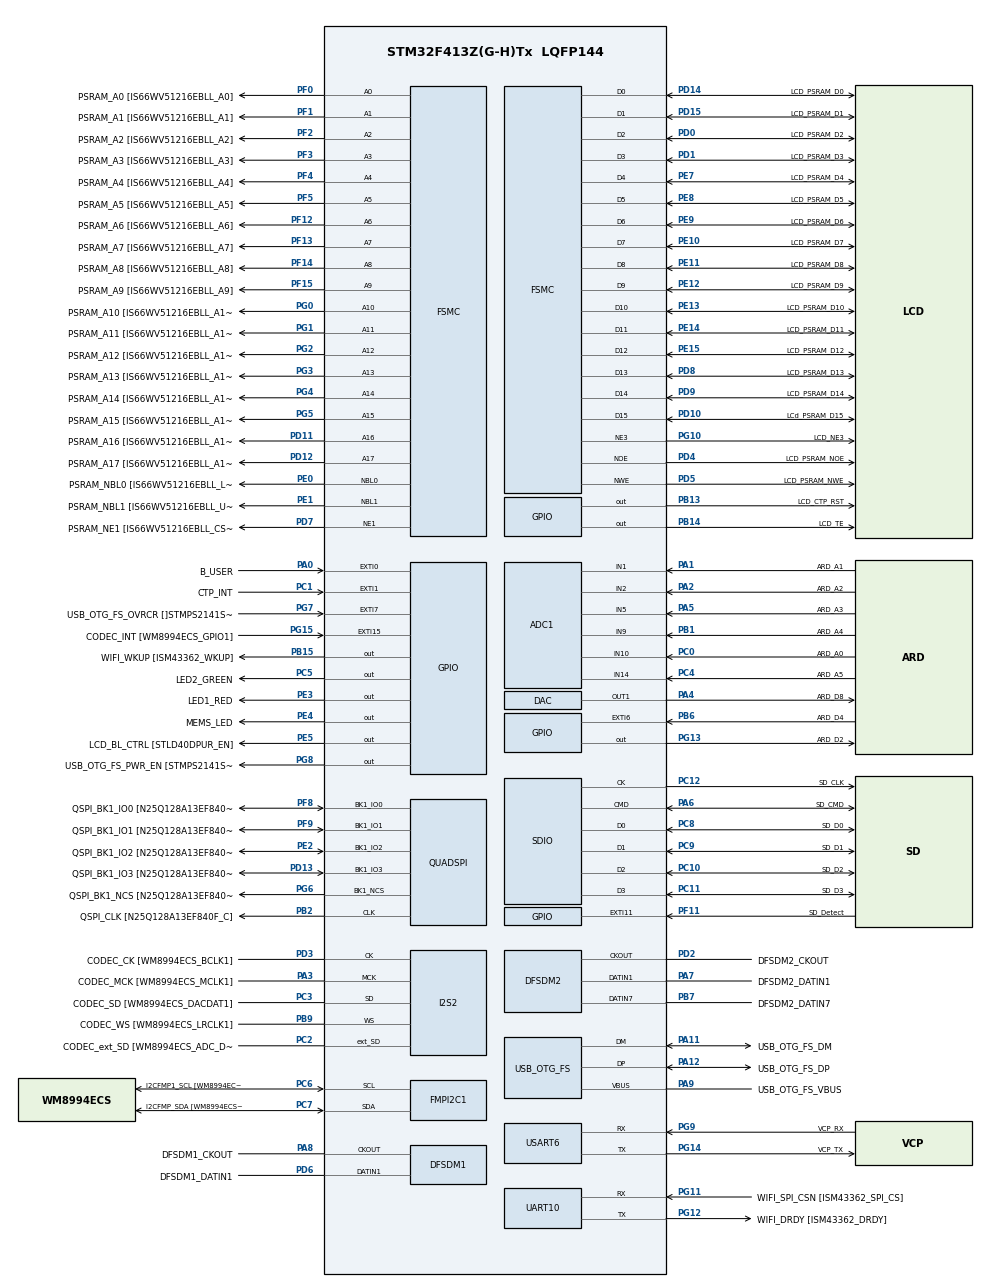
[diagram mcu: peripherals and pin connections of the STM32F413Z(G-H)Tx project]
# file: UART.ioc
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SH.FSMC_D1_DA1.1=FSMC_D1,16b-d2
PD7.Mode=NorPsramChipSelect1_1
PD12.GPIO_Label=PSRAM_A17 [IS66WV51216EBLL_A17]
SH.FSMC_D1_DA1.0=FSMC_D1,16b-d1
NVIC.TIM6_DAC_IRQn=true\:0\:0\:false\:false\:true\:false\:false\:true
PG8.Signal=GPIO_Output
SH.FSMC_NWE.0=FSMC_NWE,Sram1
PG0.Signal=FSMC_A10
SH.FSMC_NWE.1=FSMC_NWE,Lcd2
USB_HOST.USBH_USE_OS-CDC_FS=0
PG15.GPIO_Label=CODEC_INT [WM8994ECS_GPIO1]
PF7.Signal=UART7_TX
PB6.Signal=GPXTI6
PC7.Signal=FMPI2C1_SDA
PD0.Signal=FSMC_D2_DA2
PD8.Signal=FSMC_D13_DA13
PE1.Signal=FSMC_NBL1
USB_OTG_FS.phy_itface=HCD_PHY_EMBEDDED
PF1.GPIO_Label=PSRAM_A1 [IS66WV51216EBLL_A1]
PD1.GPIO_Label=LCD_PSRAM_D3
PB12.GPIO_Label=ARD_D13 [ISM43362_SCK]
PG14.Mode=Asynchronous
PF12.GPIO_Label=PSRAM_A6 [IS66WV51216EBLL_A6]
SH.FSMC_D10_DA10.0=FSMC_D10,16b-d1
PC4.GPIO_Label=ARD_A5
PE9.Signal=FSMC_D6_DA6
SH.FSMC_D10_DA10.1=FSMC_D10,16b-d2
PB1.GPIO_Label=ARD_A4
PE4.GPIO_Label=MEMS_LED
PG4.GPIO_Label=PSRAM_A14 [IS66WV51216EBLL_A14]
PC9.Mode=SD_4_bits_Wide_bus
PA8.Signal=S_CKOUTDFSDM1
SH.FSMC_D5_DA5.0=FSMC_D5,16b-d1
SH.FSMC_D5_DA5.1=FSMC_D5,16b-d2
PA0.Signal=GPXTI0
Mcu.Package=LQFP144
PB9.Signal=I2S2_WS
PB1.Signal=ADCx_IN9
NVIC.TimeBase=TIM6_DAC_IRQn
PD12.Signal=FSMC_A17
NVIC.TimeBaseIP=TIM6
PA10.Signal=USB_OTG_FS_ID
PE12.GPIO_Label=LCD_PSRAM_D9
PC11.Mode=SD_4_bits_Wide_bus
SH.FSMC_A1.0=FSMC_A1,18b-a1
PA4.GPIO_Label=ARD_D8
PD15.Signal=FSMC_D1_DA1
PG12.Signal=UART10_TX
FREERTOS.Tasks01=blink01,24,1028,DefaultThread,Default,NULL,Dynamic,NULL,NULL;mainThread,8,256,MainThread,Default,NULL,Dynamic,NULL,NULL
SH.FSMC_A16.0=FSMC_A16,18b-a1
PG5.Signal=FSMC_A15
PD3.Signal=I2S2_CK
SH.FSMC_D9_DA9.1=FSMC_D9,16b-d2
PH1\ -\ OSC_OUT.Mode=HSE-External-Clock-Source
PG9.Mode=Asynchronous
PC2.Signal=I2S2_ext_SD
SH.FSMC_D9_DA9.0=FSMC_D9,16b-d1
PC14-OSC32_IN.Signal=RCC_OSC32_IN
SH.FSMC_D8_DA8.0=FSMC_D8,16b-d1
SH.FSMC_D8_DA8.1=FSMC_D8,16b-d2
PF8.GPIO_Label=QSPI_BK1_IO0 [N25Q128A13EF840F_DQ0]
PD10.Signal=FSMC_D15_DA15
PA3.Mode=Master_Clock_Activated
PB8.GPIO_Label=ARD_D9
PA8.GPIO_Label=DFSDM1_CKOUT
SH.FSMC_A3.0=FSMC_A3,18b-a1
PE8.GPIO_Label=LCD_PSRAM_D5
PB14.Signal=GPIO_Output
PA5.Signal=ADCx_IN5
PC12.Mode=SD_4_bits_Wide_bus
PE1.GPIO_Label=PSRAM_NBL1 [IS66WV51216EBLL_UB]
PE14.Signal=FSMC_D11_DA11
PB4.GPIO_Label=ARD_D12 [ISM43362_MISO]
PB15.GPIO_Label=WIFI_WKUP [ISM43362_WKUP]
PG7.GPIO_Label=USB_OTG_FS_OVRCR []STMPS2141STR_FAULT]
PF4.GPIO_Label=PSRAM_A4 [IS66WV51216EBLL_A4]
PA1.GPIO_Label=ARD_A1
PF13.Signal=FSMC_A7
PC7.GPIO_Label=I2CFMP_SDA [WM8994ECS_SDA]
PC8.Mode=SD_4_bits_Wide_bus
ADC1.master=1
PA5.GPIO_Label=ARD_A3
PE5.GPIO_Label=LCD_BL_CTRL [STLD40DPUR_EN]
PC12.GPIO_Label=SD_CLK
ProjectManager.HeapSize=0x200
USB_HOST.USBH_HandleTypeDef=hUsbHostFS
NVIC.PriorityGroup=NVIC_PRIORITYGROUP_4
SH.FSMC_A5.0=FSMC_A5,18b-a1
PF0.GPIO_Label=PSRAM_A0 [IS66WV51216EBLL_A0]
PE3.Signal=GPIO_Output
PF4.Signal=FSMC_A4
PD2.Signal=S_CKOUTDFSDM2
Mcu.Family=STM32F4
PA6.Mode=SD_4_bits_Wide_bus
SH.FSMC_A6.0=FSMC_A6,18b-a1
PG2.Signal=FSMC_A12
PE11.GPIO_Label=LCD_PSRAM_D8
SH.FSMC_D0_DA0.1=FSMC_D0,16b-d2
PA0.GPIO_Label=B_USER
SH.FSMC_D0_DA0.0=FSMC_D0,16b-d1
PD0.GPIO_Label=LCD_PSRAM_D2
PA11.Mode=Host_Only
PB13.GPIO_Label=LCD_CTP_RST
PG5.GPIO_Label=PSRAM_A15 [IS66WV51216EBLL_A15]
PB15.Signal=GPIO_Output
PG11.Signal=UART10_RX
PG15.Signal=GPXTI15
PD13.Signal=QUADSPI_BK1_IO3
SH.S_DATAIN7DFSDM2.0=DFSDM2_DATIN7,Manchester_input_from_ch7
PA15.GPIO_Label=ARD_D10
SH.FSMC_A11.0=FSMC_A11,18b-a1
PH0\ -\ OSC_IN.Signal=RCC_OSC_IN
USB_HOST0.BSP.ip=GPIO
ADC1.Channel-0\#ChannelRegularConversion=ADC_CHANNEL_10
SH.FSMC_NBL0.0=FSMC_NBL0,2ByteEnable1
SH.FSMC_D14_DA14.1=FSMC_D14,16b-d2
PF9.Mode=Single Bank 1
SH.FSMC_D14_DA14.0=FSMC_D14,16b-d1
PC14-OSC32_IN.Mode=LSE-External-Oscillator
PA14.Mode=Serial_Wire
PF11.Signal=GPXTI11
SH.FSMC_D6_DA6.0=FSMC_D6,16b-d1
PC11.GPIO_Label=SD_D3
SH.FSMC_D6_DA6.1=FSMC_D6,16b-d2
SH.FSMC_A8.0=FSMC_A8,18b-a1
PB7.Signal=S_DATAIN7DFSDM2
SH.FSMC_D4_DA4.1=FSMC_D4,16b-d2
SH.FSMC_D4_DA4.0=FSMC_D4,16b-d1
PB7.GPIO_Label=DFSDM2_DATIN7
PD13.GPIO_Label=QSPI_BK1_IO3 [N25Q128A13EF840F_DQ3]
PA6.Signal=SDIO_CMD
USART6.VirtualMode=VM_ASYNC
PD5.GPIO_Label=LCD_PSRAM_NWE
NVIC.OTG_FS_IRQn=true\:0\:0\:false\:false\:true\:false\:true\:true
FMPI2C1.Timing=0x00303D5B
SH.FSMC_D13_DA13.0=FSMC_D13,16b-d1
SH.FSMC_D13_DA13.1=FSMC_D13,16b-d2
PA15.Signal=S_TIM2_CH1_ETR
PF8.Signal=QUADSPI_BK1_IO0
PG0.GPIO_Label=PSRAM_A10 [IS66WV51216EBLL_A10]
SH.FSMC_A13.0=FSMC_A13,18b-a1
USB_HOST0.BSP.name=Drive_VBUS_FS
SH.ADCx_IN1.0=ADC1_IN1,IN1
PB5.GPIO_Label=ARD_D11 [ISM43362_MOSI]
SH.FSMC_D2_DA2.1=FSMC_D2,16b-d2
SH.FSMC_D2_DA2.0=FSMC_D2,16b-d1
PG11.GPIO_Label=WIFI_SPI_CSN [ISM43362_SPI_CS]
PC5.Signal=GPIO_Output
PD3.GPIO_Label=CODEC_CK [WM8994ECS_BCLK1]
PE7.Signal=FSMC_D4_DA4
PD6.Signal=S_DATAIN1DFSDM1
PF3.GPIO_Label=PSRAM_A3 [IS66WV51216EBLL_A3]
SH.S_DATAIN1DFSDM1.0=DFSDM1_DATIN1,Manchester_input_from_ch1
PE2.GPIO_Label=QSPI_BK1_IO2 [N25Q128A13EF840F_DQ2]
PB4.Signal=SPI3_MISO
PG2.GPIO_Label=PSRAM_A12 [IS66WV51216EBLL_A12]
PA3.Signal=I2S2_MCK
SH.FSMC_D12_DA12.0=FSMC_D12,16b-d1
SH.FSMC_D12_DA12.1=FSMC_D12,16b-d2
PD15.GPIO_Label=LCD_PSRAM_D1
PG7.Signal=GPXTI7
PC9.GPIO_Label=SD_D1
PC11.Signal=SDIO_D3
PC8.Signal=SDIO_D0
USB_HOST0.BSP.solution=PG8
PC10.Mode=SD_4_bits_Wide_bus
PC2.Mode=Full_Duplex_Master
PE14.GPIO_Label=LCD_PSRAM_D11
PD9.Signal=FSMC_D14_DA14
SH.S_TIM3_CH3.0=TIM3_CH3
PA12.GPIO_Label=USB_OTG_FS_DP
PD8.GPIO_Label=LCD_PSRAM_D13
PG8.GPIO_Label=USB_OTG_FS_PWR_EN [STMPS2141STR_EN]
PA13.Signal=SYS_JTMS-SWDIO
PA9.Mode=Activate_VBUS
PH0\ -\ OSC_IN.Mode=HSE-External-Clock-Source
PF6.Signal=UART7_RX
PB10.GPIO_Label=ARD_D15
SH.S_TIM4_CH3.0=TIM4_CH3
PB9.Mode=Full_Duplex_Master
RCC.USBFreq_Value=48000000
PF9.GPIO_Label=QSPI_BK1_IO1 [N25Q128A13EF840F_DQ1]
PD10.GPIO_Label=LCd_PSRAM_D15
PA1.Signal=ADCx_IN1
board=STM32F413H-DISCO
PG12.Mode=Asynchronous
RCC.VCOOutputFreq_Value=240000000
PC1.GPIO_Label=CTP_INT
PF15.GPIO_Label=PSRAM_A9 [IS66WV51216EBLL_A9]
PF1.Signal=FSMC_A1
PE0.Signal=FSMC_NBL0
PE7.GPIO_Label=LCD_PSRAM_D4
PE12.Signal=FSMC_D9_DA9
PH1\ -\ OSC_OUT.GPIO_Label=WIFI_RST [ISM43362_RSTN]
I2S2.ErrorAudioFreq=1.72 %
VP_USB_HOST_VS_USB_HOST_CDC_FS.Mode=CDC_FS
PB2.Mode=Single Bank 1
PB2.GPIO_Label=QSPI_CLK [N25Q128A13EF840F_C]
SH.FSMC_D11_DA11.1=FSMC_D11,16b-d2
SH.FSMC_D11_DA11.0=FSMC_D11,16b-d1
SH.FSMC_NOE.1=FSMC_NOE,Lcd2
SH.FSMC_NOE.0=FSMC_NOE,Sram1
SH.S_CKOUTDFSDM2.0=DFSDM2_CKOUT,CKOUT
RCC.PLLQ=5
RCC.PLLM=15
RCC.PLLN=144
PH0\ -\ OSC_IN.GPIO_Label=STLK_MCO
I2S2.RealAudioFreq=8.138 KHz
RCC.PLLI2SN=50
PB12.Signal=SPI3_SCK
PA3.GPIO_Label=CODEC_MCK [WM8994ECS_MCLK1]
RCC.PLLI2SM=12
USB_HOST0.BSP.instance=PG8
VP_SYS_VS_tim6.Mode=TIM6
PG4.Signal=FSMC_A14
PC12.Signal=SDIO_CK
PB14.GPIO_Label=LCD_TE
PA14.GPIO_Label=STLINK_JTMS_SWCLK
PG6.GPIO_Label=QSPI_BK1_NCS [N25Q128A13EF840F_S]
PC6.GPIO_Label=I2CFMP1_SCL [WM8994ECS_CLK]
PA6.GPIO_Label=SD_CMD
PB6.GPIO_Label=ARD_D4
PB13.Signal=GPIO_Output
PG6.Mode=Single Bank 1
PD6.GPIO_Label=DFSDM1_DATIN1
PG13.Signal=GPIO_Output
PC15-OSC32_OUT.GPIO_Label=OSC32_OUT
PE6.GPIO_Label=ARD_D5
PF6.GPIO_Label=ARD_D0
PE2.Mode=Single Bank 1
PD4.Signal=FSMC_NOE
PC3.Signal=I2S2_SD
PE5.Signal=GPIO_Output
PF10.GPIO_Label=ARD_D3
PB2.Signal=QUADSPI_CLK
SH.FSMC_A0.0=FSMC_A0,A0_2
SH.FSMC_A0.1=FSMC_A0,18b-a1
PE2.Signal=QUADSPI_BK1_IO2
PF8.Mode=Single Bank 1
PF3.Signal=FSMC_A3
PD3.Mode=Full_Duplex_Master
PE10.Signal=FSMC_D7_DA7
ADC1.SamplingTime-0\#ChannelRegularConversion=ADC_SAMPLETIME_3CYCLES
SH.ADCx_IN14.0=ADC1_IN14,IN14
SH.ADCx_IN9.0=ADC1_IN9,IN9
SH.FSMC_D3_DA3.1=FSMC_D3,16b-d2
SH.FSMC_D3_DA3.0=FSMC_D3,16b-d1
PF14.Signal=FSMC_A8
PE10.GPIO_Label=LCD_PSRAM_D7
ADC1.Rank-0\#ChannelRegularConversion=1
PD9.GPIO_Label=LCD_PSRAM_D14
SH.FSMC_A2.0=FSMC_A2,18b-a1
PG9.Signal=USART6_RX
PA9.GPIO_Label=USB_OTG_FS_VBUS
PC6.Signal=FMPI2C1_SCL
PB11.GPIO_Label=ARD_D14
PD7.Signal=FSMC_NE1
PD1.Signal=FSMC_D3_DA3
PA11.GPIO_Label=USB_OTG_FS_DM
PF14.GPIO_Label=PSRAM_A8 [IS66WV51216EBLL_A8]
PC0.Signal=ADCx_IN10
PF13.GPIO_Label=PSRAM_A7 [IS66WV51216EBLL_A7]
PG13.GPIO_Label=ARD_D2
PG10.Signal=FSMC_NE3
USB_HOST0.BSP.STBoard=false
SH.FSMC_A15.0=FSMC_A15,18b-a1
SH.S_TIM9_CH2.0=TIM9_CH2
PC6.Mode=I2C
PA9.Signal=USB_OTG_FS_VBUS
I2S2.VirtualMode=I2S_MODE_MASTER
PE9.GPIO_Label=LCD_PSRAM_D6
PB10.Signal=I2C2_SCL
SH.FSMC_D7_DA7.1=FSMC_D7,16b-d2
PH1\ -\ OSC_OUT.Signal=RCC_OSC_OUT
SH.FSMC_D7_DA7.0=FSMC_D7,16b-d1
USB_HOST.VirtualModeFS=Cdc
RCC.SDIOCLockSelection=RCC_SDIOCLKSOURCE_SYSCLK
PE15.Signal=FSMC_D12_DA12
PE8.Signal=FSMC_D5_DA5
SH.FSMC_A4.0=FSMC_A4,18b-a1
UART10.VirtualMode=Asynchronous
PA13.Mode=Serial_Wire
PG14.GPIO_Label=VCP_TX
I2S2.FullDuplexMode=I2S_FULLDUPLEXMODE_ENABLE
PA4.Signal=COMP_DAC1_group
PB5.Signal=SPI3_MOSI
PE13.GPIO_Label=LCD_PSRAM_D10
PD11.Signal=FSMC_A16
PG11.Mode=Asynchronous
PA11.Signal=USB_OTG_FS_DM
SH.FSMC_D15_DA15.1=FSMC_D15,16b-d2
SH.S_TIM2_CH1_ETR.0=TIM2_CH1
SH.FSMC_D15_DA15.0=FSMC_D15,16b-d1
SH.FSMC_A17.0=FSMC_A17,18b-a1
PF9.Signal=QUADSPI_BK1_IO1
SH.ADCx_IN5.0=ADC1_IN5,IN5
PC3.GPIO_Label=CODEC_SD [WM8994ECS_DACDAT1]
PG3.GPIO_Label=PSRAM_A13 [IS66WV51216EBLL_A13]
PB0.Signal=S_TIM3_CH3
USB_HOST0.BSP.mode=Output
PC1.Signal=GPXTI1
PD2.GPIO_Label=DFSDM2_CKOUT
PG10.GPIO_Label=LCD_NE3
PC3.Mode=Full_Duplex_Master
RCC.CortexFreq_Value=16000000
PG6.Signal=QUADSPI_BK1_NCS
SH.FSMC_A12.0=FSMC_A12,18b-a1
SH.ADCx_IN2.0=ADC1_IN2,IN2
PC10.Signal=SDIO_D2
PC0.GPIO_Label=ARD_A0
PB0.GPIO_Label=ARD_D6
SH.S_DATAIN1DFSDM2.0=DFSDM2_DATIN1,Manchester_input_from_ch1
PB11.Signal=I2C2_SDA
ProjectManager.StackSize=0x400
VP_FREERTOS_VS_CMSIS_V2.Mode=CMSIS_V2
PA12.Signal=USB_OTG_FS_DP
SH.FSMC_A7.0=FSMC_A7,18b-a1
PD11.GPIO_Label=PSRAM_A16 [IS66WV51216EBLL_A16]
PF11.GPIO_Label=SD_Detect
PF12.Signal=FSMC_A6
SH.FSMC_A10.0=FSMC_A10,18b-a1
PE13.Signal=FSMC_D10_DA10
PF7.GPIO_Label=ARD_D1
SH.FSMC_A14.0=FSMC_A14,18b-a1
PA10.GPIO_Label=USB_OTG_FS_ID
USB_HOST0.BSP.i2creg=0
PE4.Signal=GPIO_Output
PD7.GPIO_Label=PSRAM_NE1 [IS66WV51216EBLL_CS1]
USB_HOST0.BSP.i2caddr=0
SH.FSMC_NBL1.0=FSMC_NBL1,2ByteEnable1
PA2.GPIO_Label=ARD_A2
PF5.GPIO_Label=PSRAM_A5 [IS66WV51216EBLL_A5]
USB_OTG_FS.VirtualMode=Host_Only
PE0.GPIO_Label=PSRAM_NBL0 [IS66WV51216EBLL_LB]
PF5.Signal=FSMC_A5
SH.FSMC_A9.0=FSMC_A9,18b-a1
PC14-OSC32_IN.GPIO_Label=OSC32_IN
PF0.Signal=FSMC_A0
PC2.GPIO_Label=CODEC_ext_SD [WM8994ECS_ADC_DAT1]
PB3.GPIO_Label=STLINK_JTDO_SWCLK
PC15-OSC32_OUT.Mode=LSE-External-Oscillator
SH.COMP_DAC1_group.0=DAC_OUT1,DAC_OUT1
I2S2.Instance=SPI$Index
PB9.GPIO_Label=CODEC_WS [WM8994ECS_LRCLK1]
PC10.GPIO_Label=SD_D2
PG3.Signal=FSMC_A13
PG1.Signal=FSMC_A11
PC4.Signal=ADCx_IN14
PG10.Mode=NorPsramChipSelect3_2
USB_HOST.BSP.number=1
PD5.Signal=FSMC_NWE
NVIC.USART6_IRQn=true\:0\:0\:false\:false\:true\:false\:true\:true
PC8.GPIO_Label=SD_D0
PE15.GPIO_Label=LCD_PSRAM_D12
ProjectManager.TargetToolchain=STM32CubeIDE
PD13.Mode=Single Bank 1
PF2.Signal=FSMC_A2
PE11.Signal=FSMC_D8_DA8
PC15-OSC32_OUT.Signal=RCC_OSC32_OUT
PG9.GPIO_Label=VCP_RX
PG14.Signal=USART6_TX
PG1.GPIO_Label=PSRAM_A11 [IS66WV51216EBLL_A11]
USB_HOST0.BSP.api=Unknown
PD4.GPIO_Label=LCD_PSRAM_NOE
PF10.Signal=S_TIM5_CH4
SH.S_CKOUTDFSDM1.0=DFSDM1_CKOUT,CKOUT
SH.S_TIM5_CH4.0=TIM5_CH4
PF15.Signal=FSMC_A9
PD14.GPIO_Label=LCD_PSRAM_D0
PE6.Signal=S_TIM9_CH2
Mcu.Name=STM32F413Z(G-H)Tx
PA2.Signal=ADCx_IN2
PA13.GPIO_Label=STLINK_JTMS_SWDIO
PD14.Signal=FSMC_D0_DA0
PB3.Signal=SYS_JTDO-SWO
PA7.GPIO_Label=DFSDM2_DATIN1
PA12.Mode=Host_Only
PC5.GPIO_Label=LED2_GREEN
PA14.Signal=SYS_JTCK-SWCLK
SH.ADCx_IN10.0=ADC1_IN10,IN10
PG12.GPIO_Label=WIFI_DRDY [ISM43362_DRDY]
ADC1.NbrOfConversionFlag=1
PB8.Signal=S_TIM4_CH3
PE3.GPIO_Label=LED1_RED
PC9.Signal=SDIO_D1
PC7.Mode=I2C
PA7.Signal=S_DATAIN1DFSDM2
PF2.GPIO_Label=PSRAM_A2 [IS66WV51216EBLL_A2]

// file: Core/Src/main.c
/* USER CODE BEGIN Header */
/**
  ******************************************************************************
  * @file           : main.c
  * @brief          : Main program body
  ******************************************************************************
  * @attention
  *
  * <h2><center>&copy; Copyright (c) 2021 STMicroelectronics.
  * All rights reserved.</center></h2>
  *
  * This software component is licensed by ST under Ultimate Liberty license
  * SLA0044, the "License"; You may not use this file except in compliance with
  * the License. You may obtain a copy of the License at:
  *                             www.st.com/SLA0044
  *
  ******************************************************************************
  */
/* USER CODE END Header */
#include "main.h"
#include "cmsis_os.h"
#include "usb_host.h"

ADC_HandleTypeDef hadc1;

DAC_HandleTypeDef hdac;

DFSDM_Channel_HandleTypeDef hdfsdm1_channel1;
DFSDM_Channel_HandleTypeDef hdfsdm2_channel1;
DFSDM_Channel_HandleTypeDef hdfsdm2_channel7;

FMPI2C_HandleTypeDef hfmpi2c1;

I2S_HandleTypeDef hi2s2;

QSPI_HandleTypeDef hqspi;

SD_HandleTypeDef hsd;

UART_HandleTypeDef huart10;
UART_HandleTypeDef huart6;

SRAM_HandleTypeDef hsram1;
SRAM_HandleTypeDef hsram2;

/* Definitions for blink01 */
osThreadId_t blink01Handle;
const osThreadAttr_t blink01_attributes = {
  .name = "blink01",
  .priority = (osPriority_t) osPriorityNormal,
  .stack_size = 128 * 4
};
/* Definitions for mainThread */
osThreadId_t mainThreadHandle;
const osThreadAttr_t mainThread_attributes = {
  .name = "mainThread",
  .priority = (osPriority_t) osPriorityLow,
  .stack_size = 128 * 4
};
/* USER CODE BEGIN PV */
uint8_t Rx_Data[10];
/* USER CODE END PV */

void SystemClock_Config(void);
static void MX_GPIO_Init(void);
static void MX_ADC1_Init(void);
static void MX_DAC_Init(void);
static void MX_DFSDM1_Init(void);
static void MX_DFSDM2_Init(void);
static void MX_FMPI2C1_Init(void);
static void MX_FSMC_Init(void);
static void MX_I2S2_Init(void);
static void MX_QUADSPI_Init(void);
static void MX_SDIO_SD_Init(void);
static void MX_UART10_Init(void);
static void MX_USART6_UART_Init(void);
void DefaultThread(void *argument);
void MainThread(void *argument);

/* USER CODE BEGIN PFP */
void HAL_UART_RxCpltCallback(UART_HandleTypeDef *huart)
{
	HAL_UART_Receive_IT(&huart6, Rx_Data, 4);
	HAL_GPIO_TogglePin(GPIOE, GPIO_PIN_3);
	HAL_UART_Transmit(&huart6, Rx_Data, 4, 10);
}
/* USER CODE END PFP */

int main(void)
{

  /* MCU Configuration--------------------------------------------------------*/

  /* Reset of all peripherals, Initializes the Flash interface and the Systick. */
  HAL_Init();

  /* Configure the system clock */
  SystemClock_Config();

  /* Initialize all configured peripherals */
  MX_GPIO_Init();
  MX_ADC1_Init();
  MX_DAC_Init();
  MX_DFSDM1_Init();
  MX_DFSDM2_Init();
  MX_FMPI2C1_Init();
  MX_FSMC_Init();
  MX_I2S2_Init();
  MX_QUADSPI_Init();
  MX_SDIO_SD_Init();
  MX_UART10_Init();
  MX_USART6_UART_Init();

  /* Init scheduler */
  osKernelInitialize();

  /* Create the thread(s) */
  /* creation of blink01 */
  blink01Handle = osThreadNew(DefaultThread, NULL, &blink01_attributes);

  /* creation of mainThread */
  mainThreadHandle = osThreadNew(MainThread, NULL, &mainThread_attributes);

  /* Start scheduler */
  osKernelStart();

  /* We should never get here as control is now taken by the scheduler */
  /* Infinite loop */
  while (1)
  {

  }
}

void SystemClock_Config(void)
{
  RCC_OscInitTypeDef RCC_OscInitStruct = {0};
  RCC_ClkInitTypeDef RCC_ClkInitStruct = {0};
  RCC_PeriphCLKInitTypeDef PeriphClkInitStruct = {0};

  /** Configure the main internal regulator output voltage
  */
  __HAL_RCC_PWR_CLK_ENABLE();
  __HAL_PWR_VOLTAGESCALING_CONFIG(PWR_REGULATOR_VOLTAGE_SCALE1);
  /** Initializes the RCC Oscillators according to the specified parameters
  * in the RCC_OscInitTypeDef structure.
  */
  RCC_OscInitStruct.OscillatorType = RCC_OSCILLATORTYPE_HSI|RCC_OSCILLATORTYPE_HSE;
  RCC_OscInitStruct.HSEState = RCC_HSE_BYPASS;
  RCC_OscInitStruct.HSIState = RCC_HSI_ON;
  RCC_OscInitStruct.HSICalibrationValue = RCC_HSICALIBRATION_DEFAULT;
  RCC_OscInitStruct.PLL.PLLState = RCC_PLL_ON;
  RCC_OscInitStruct.PLL.PLLSource = RCC_PLLSOURCE_HSE;
  RCC_OscInitStruct.PLL.PLLM = 15;
  RCC_OscInitStruct.PLL.PLLN = 144;
  RCC_OscInitStruct.PLL.PLLP = RCC_PLLP_DIV2;
  RCC_OscInitStruct.PLL.PLLQ = 5;
  RCC_OscInitStruct.PLL.PLLR = 2;
  if (HAL_RCC_OscConfig(&RCC_OscInitStruct) != HAL_OK)
  {
    Error_Handler();
  }
  /** Initializes the CPU, AHB and APB buses clocks
  */
  RCC_ClkInitStruct.ClockType = RCC_CLOCKTYPE_HCLK|RCC_CLOCKTYPE_SYSCLK
                              |RCC_CLOCKTYPE_PCLK1|RCC_CLOCKTYPE_PCLK2;
  RCC_ClkInitStruct.SYSCLKSource = RCC_SYSCLKSOURCE_HSI;
  RCC_ClkInitStruct.AHBCLKDivider = RCC_SYSCLK_DIV1;
  RCC_ClkInitStruct.APB1CLKDivider = RCC_HCLK_DIV1;
  RCC_ClkInitStruct.APB2CLKDivider = RCC_HCLK_DIV1;

  if (HAL_RCC_ClockConfig(&RCC_ClkInitStruct, FLASH_LATENCY_0) != HAL_OK)
  {
    Error_Handler();
  }
  PeriphClkInitStruct.PeriphClockSelection = RCC_PERIPHCLK_I2S_APB1|RCC_PERIPHCLK_DFSDM1
                              |RCC_PERIPHCLK_SDIO|RCC_PERIPHCLK_CLK48
                              |RCC_PERIPHCLK_FMPI2C1;
  PeriphClkInitStruct.PLLI2S.PLLI2SN = 50;
  PeriphClkInitStruct.PLLI2S.PLLI2SM = 12;
  PeriphClkInitStruct.PLLI2S.PLLI2SR = 2;
  PeriphClkInitStruct.PLLI2S.PLLI2SQ = 2;
  PeriphClkInitStruct.Clk48ClockSelection = RCC_CLK48CLKSOURCE_PLLQ;
  PeriphClkInitStruct.Dfsdm1ClockSelection = RCC_DFSDM1CLKSOURCE_APB2;
  PeriphClkInitStruct.SdioClockSelection = RCC_SDIOCLKSOURCE_SYSCLK;
  PeriphClkInitStruct.PLLI2SSelection = RCC_PLLI2SCLKSOURCE_PLLSRC;
  PeriphClkInitStruct.I2sApb1ClockSelection = RCC_I2SAPB1CLKSOURCE_PLLI2S;
  PeriphClkInitStruct.Fmpi2c1ClockSelection = RCC_FMPI2C1CLKSOURCE_APB;
  if (HAL_RCCEx_PeriphCLKConfig(&PeriphClkInitStruct) != HAL_OK)
  {
    Error_Handler();
  }
}

static void MX_ADC1_Init(void)
{

  ADC_ChannelConfTypeDef sConfig = {0};

  /** Configure the global features of the ADC (Clock, Resolution, Data Alignment and number of conversion)
  */
  hadc1.Instance = ADC1;
  hadc1.Init.ClockPrescaler = ADC_CLOCK_SYNC_PCLK_DIV2;
  hadc1.Init.Resolution = ADC_RESOLUTION_12B;
  hadc1.Init.ScanConvMode = DISABLE;
  hadc1.Init.ContinuousConvMode = DISABLE;
  hadc1.Init.DiscontinuousConvMode = DISABLE;
  hadc1.Init.ExternalTrigConvEdge = ADC_EXTERNALTRIGCONVEDGE_NONE;
  hadc1.Init.ExternalTrigConv = ADC_SOFTWARE_START;
  hadc1.Init.DataAlign = ADC_DATAALIGN_RIGHT;
  hadc1.Init.NbrOfConversion = 1;
  hadc1.Init.DMAContinuousRequests = DISABLE;
  hadc1.Init.EOCSelection = ADC_EOC_SINGLE_CONV;
  if (HAL_ADC_Init(&hadc1) != HAL_OK)
  {
    Error_Handler();
  }
  /** Configure for the selected ADC regular channel its corresponding rank in the sequencer and its sample time.
  */
  sConfig.Channel = ADC_CHANNEL_10;
  sConfig.Rank = 1;
  sConfig.SamplingTime = ADC_SAMPLETIME_3CYCLES;
  if (HAL_ADC_ConfigChannel(&hadc1, &sConfig) != HAL_OK)
  {
    Error_Handler();
  }

}

static void MX_DAC_Init(void)
{

  DAC_ChannelConfTypeDef sConfig = {0};

  /** DAC Initialization
  */
  hdac.Instance = DAC;
  if (HAL_DAC_Init(&hdac) != HAL_OK)
  {
    Error_Handler();
  }
  /** DAC channel OUT1 config
  */
  sConfig.DAC_Trigger = DAC_TRIGGER_NONE;
  sConfig.DAC_OutputBuffer = DAC_OUTPUTBUFFER_ENABLE;
  if (HAL_DAC_ConfigChannel(&hdac, &sConfig, DAC_CHANNEL_1) != HAL_OK)
  {
    Error_Handler();
  }

}

static void MX_DFSDM1_Init(void)
{

  hdfsdm1_channel1.Instance = DFSDM1_Channel1;
  hdfsdm1_channel1.Init.OutputClock.Activation = ENABLE;
  hdfsdm1_channel1.Init.OutputClock.Selection = DFSDM_CHANNEL_OUTPUT_CLOCK_SYSTEM;
  hdfsdm1_channel1.Init.OutputClock.Divider = 2;
  hdfsdm1_channel1.Init.Input.Multiplexer = DFSDM_CHANNEL_EXTERNAL_INPUTS;
  hdfsdm1_channel1.Init.Input.DataPacking = DFSDM_CHANNEL_STANDARD_MODE;
  hdfsdm1_channel1.Init.Input.Pins = DFSDM_CHANNEL_SAME_CHANNEL_PINS;
  hdfsdm1_channel1.Init.SerialInterface.Type = DFSDM_CHANNEL_MANCHESTER_RISING;
  hdfsdm1_channel1.Init.SerialInterface.SpiClock = DFSDM_CHANNEL_SPI_CLOCK_EXTERNAL;
  hdfsdm1_channel1.Init.Awd.FilterOrder = DFSDM_CHANNEL_FASTSINC_ORDER;
  hdfsdm1_channel1.Init.Awd.Oversampling = 1;
  hdfsdm1_channel1.Init.Offset = 0;
  hdfsdm1_channel1.Init.RightBitShift = 0x00;
  if (HAL_DFSDM_ChannelInit(&hdfsdm1_channel1) != HAL_OK)
  {
    Error_Handler();
  }

}

static void MX_DFSDM2_Init(void)
{

  hdfsdm2_channel1.Instance = DFSDM2_Channel1;
  hdfsdm2_channel1.Init.OutputClock.Activation = ENABLE;
  hdfsdm2_channel1.Init.OutputClock.Selection = DFSDM_CHANNEL_OUTPUT_CLOCK_SYSTEM;
  hdfsdm2_channel1.Init.OutputClock.Divider = 2;
  hdfsdm2_channel1.Init.Input.Multiplexer = DFSDM_CHANNEL_EXTERNAL_INPUTS;
  hdfsdm2_channel1.Init.Input.DataPacking = DFSDM_CHANNEL_STANDARD_MODE;
  hdfsdm2_channel1.Init.Input.Pins = DFSDM_CHANNEL_SAME_CHANNEL_PINS;
  hdfsdm2_channel1.Init.SerialInterface.Type = DFSDM_CHANNEL_MANCHESTER_RISING;
  hdfsdm2_channel1.Init.SerialInterface.SpiClock = DFSDM_CHANNEL_SPI_CLOCK_EXTERNAL;
  hdfsdm2_channel1.Init.Awd.FilterOrder = DFSDM_CHANNEL_FASTSINC_ORDER;
  hdfsdm2_channel1.Init.Awd.Oversampling = 1;
  hdfsdm2_channel1.Init.Offset = 0;
  hdfsdm2_channel1.Init.RightBitShift = 0x00;
  if (HAL_DFSDM_ChannelInit(&hdfsdm2_channel1) != HAL_OK)
  {
    Error_Handler();
  }
  hdfsdm2_channel7.Instance = DFSDM2_Channel7;
  hdfsdm2_channel7.Init.OutputClock.Activation = ENABLE;
  hdfsdm2_channel7.Init.OutputClock.Selection = DFSDM_CHANNEL_OUTPUT_CLOCK_SYSTEM;
  hdfsdm2_channel7.Init.OutputClock.Divider = 2;
  hdfsdm2_channel7.Init.Input.Multiplexer = DFSDM_CHANNEL_EXTERNAL_INPUTS;
  hdfsdm2_channel7.Init.Input.DataPacking = DFSDM_CHANNEL_STANDARD_MODE;
  hdfsdm2_channel7.Init.Input.Pins = DFSDM_CHANNEL_SAME_CHANNEL_PINS;
  hdfsdm2_channel7.Init.SerialInterface.Type = DFSDM_CHANNEL_MANCHESTER_RISING;
  hdfsdm2_channel7.Init.SerialInterface.SpiClock = DFSDM_CHANNEL_SPI_CLOCK_EXTERNAL;
  hdfsdm2_channel7.Init.Awd.FilterOrder = DFSDM_CHANNEL_FASTSINC_ORDER;
  hdfsdm2_channel7.Init.Awd.Oversampling = 1;
  hdfsdm2_channel7.Init.Offset = 0;
  hdfsdm2_channel7.Init.RightBitShift = 0x00;
  if (HAL_DFSDM_ChannelInit(&hdfsdm2_channel7) != HAL_OK)
  {
    Error_Handler();
  }

}

static void MX_FMPI2C1_Init(void)
{

  hfmpi2c1.Instance = FMPI2C1;
  hfmpi2c1.Init.Timing = 0x00303D5B;
  hfmpi2c1.Init.OwnAddress1 = 0;
  hfmpi2c1.Init.AddressingMode = FMPI2C_ADDRESSINGMODE_7BIT;
  hfmpi2c1.Init.DualAddressMode = FMPI2C_DUALADDRESS_DISABLE;
  hfmpi2c1.Init.OwnAddress2 = 0;
  hfmpi2c1.Init.OwnAddress2Masks = FMPI2C_OA2_NOMASK;
  hfmpi2c1.Init.GeneralCallMode = FMPI2C_GENERALCALL_DISABLE;
  hfmpi2c1.Init.NoStretchMode = FMPI2C_NOSTRETCH_DISABLE;
  if (HAL_FMPI2C_Init(&hfmpi2c1) != HAL_OK)
  {
    Error_Handler();
  }
  /** Configure Analogue filter
  */
  if (HAL_FMPI2CEx_ConfigAnalogFilter(&hfmpi2c1, FMPI2C_ANALOGFILTER_ENABLE) != HAL_OK)
  {
    Error_Handler();
  }

}

static void MX_I2S2_Init(void)
{

  hi2s2.Instance = SPI2;
  hi2s2.Init.Mode = I2S_MODE_MASTER_TX;
  hi2s2.Init.Standard = I2S_STANDARD_PHILIPS;
  hi2s2.Init.DataFormat = I2S_DATAFORMAT_16B;
  hi2s2.Init.MCLKOutput = I2S_MCLKOUTPUT_ENABLE;
  hi2s2.Init.AudioFreq = I2S_AUDIOFREQ_8K;
  hi2s2.Init.CPOL = I2S_CPOL_LOW;
  hi2s2.Init.ClockSource = I2S_CLOCK_PLL;
  hi2s2.Init.FullDuplexMode = I2S_FULLDUPLEXMODE_ENABLE;
  if (HAL_I2S_Init(&hi2s2) != HAL_OK)
  {
    Error_Handler();
  }

}

static void MX_QUADSPI_Init(void)
{

  /* QUADSPI parameter configuration*/
  hqspi.Instance = QUADSPI;
  hqspi.Init.ClockPrescaler = 255;
  hqspi.Init.FifoThreshold = 1;
  hqspi.Init.SampleShifting = QSPI_SAMPLE_SHIFTING_NONE;
  hqspi.Init.FlashSize = 1;
  hqspi.Init.ChipSelectHighTime = QSPI_CS_HIGH_TIME_1_CYCLE;
  hqspi.Init.ClockMode = QSPI_CLOCK_MODE_0;
  hqspi.Init.FlashID = QSPI_FLASH_ID_1;
  hqspi.Init.DualFlash = QSPI_DUALFLASH_DISABLE;
  if (HAL_QSPI_Init(&hqspi) != HAL_OK)
  {
    Error_Handler();
  }

}

static void MX_SDIO_SD_Init(void)
{

  hsd.Instance = SDIO;
  hsd.Init.ClockEdge = SDIO_CLOCK_EDGE_RISING;
  hsd.Init.ClockBypass = SDIO_CLOCK_BYPASS_DISABLE;
  hsd.Init.ClockPowerSave = SDIO_CLOCK_POWER_SAVE_DISABLE;
  hsd.Init.BusWide = SDIO_BUS_WIDE_1B;
  hsd.Init.HardwareFlowControl = SDIO_HARDWARE_FLOW_CONTROL_DISABLE;
  hsd.Init.ClockDiv = 0;
  if (HAL_SD_Init(&hsd) != HAL_OK)
  {
    Error_Handler();
  }
  if (HAL_SD_ConfigWideBusOperation(&hsd, SDIO_BUS_WIDE_4B) != HAL_OK)
  {
    Error_Handler();
  }

}

static void MX_UART10_Init(void)
{

  huart10.Instance = UART10;
  huart10.Init.BaudRate = 115200;
  huart10.Init.WordLength = UART_WORDLENGTH_8B;
  huart10.Init.StopBits = UART_STOPBITS_1;
  huart10.Init.Parity = UART_PARITY_NONE;
  huart10.Init.Mode = UART_MODE_TX_RX;
  huart10.Init.HwFlowCtl = UART_HWCONTROL_NONE;
  huart10.Init.OverSampling = UART_OVERSAMPLING_16;
  if (HAL_UART_Init(&huart10) != HAL_OK)
  {
    Error_Handler();
  }

}

static void MX_USART6_UART_Init(void)
{

  huart6.Instance = USART6;
  huart6.Init.BaudRate = 115200;
  huart6.Init.WordLength = UART_WORDLENGTH_8B;
  huart6.Init.StopBits = UART_STOPBITS_1;
  huart6.Init.Parity = UART_PARITY_NONE;
  huart6.Init.Mode = UART_MODE_TX_RX;
  huart6.Init.HwFlowCtl = UART_HWCONTROL_NONE;
  huart6.Init.OverSampling = UART_OVERSAMPLING_16;
  if (HAL_UART_Init(&huart6) != HAL_OK)
  {
    Error_Handler();
  }

}

static void MX_GPIO_Init(void)
{
  GPIO_InitTypeDef GPIO_InitStruct = {0};

  /* GPIO Ports Clock Enable */
  __HAL_RCC_GPIOE_CLK_ENABLE();
  __HAL_RCC_GPIOC_CLK_ENABLE();
  __HAL_RCC_GPIOF_CLK_ENABLE();
  __HAL_RCC_GPIOH_CLK_ENABLE();
  __HAL_RCC_GPIOA_CLK_ENABLE();
  __HAL_RCC_GPIOB_CLK_ENABLE();
  __HAL_RCC_GPIOG_CLK_ENABLE();
  __HAL_RCC_GPIOD_CLK_ENABLE();

  /*Configure GPIO pin Output Level */
  HAL_GPIO_WritePin(GPIOE, LED1_RED_Pin|MEMS_LED_Pin|LCD_BL_CTRL_Pin, GPIO_PIN_RESET);

  /*Configure GPIO pin Output Level */
  HAL_GPIO_WritePin(LED2_GREEN_GPIO_Port, LED2_GREEN_Pin, GPIO_PIN_RESET);

  /*Configure GPIO pin Output Level */
  HAL_GPIO_WritePin(GPIOB, LCD_CTP_RST_Pin|LCD_TE_Pin|WIFI_WKUP_Pin, GPIO_PIN_RESET);

  /*Configure GPIO pin Output Level */
  HAL_GPIO_WritePin(GPIOG, USB_OTG_FS_PWR_EN_Pin|ARD_D2_Pin, GPIO_PIN_RESET);

  /*Configure GPIO pins : LED1_RED_Pin MEMS_LED_Pin LCD_BL_CTRL_Pin */
  GPIO_InitStruct.Pin = LED1_RED_Pin|MEMS_LED_Pin|LCD_BL_CTRL_Pin;
  GPIO_InitStruct.Mode = GPIO_MODE_OUTPUT_PP;
  GPIO_InitStruct.Pull = GPIO_NOPULL;
  GPIO_InitStruct.Speed = GPIO_SPEED_FREQ_LOW;
  HAL_GPIO_Init(GPIOE, &GPIO_InitStruct);

  /*Configure GPIO pin : ARD_D5_Pin */
  GPIO_InitStruct.Pin = ARD_D5_Pin;
  GPIO_InitStruct.Mode = GPIO_MODE_AF_PP;
  GPIO_InitStruct.Pull = GPIO_NOPULL;
  GPIO_InitStruct.Speed = GPIO_SPEED_FREQ_LOW;
  GPIO_InitStruct.Alternate = GPIO_AF3_TIM9;
  HAL_GPIO_Init(ARD_D5_GPIO_Port, &GPIO_InitStruct);

  /*Configure GPIO pin : ARD_D3_Pin */
  GPIO_InitStruct.Pin = ARD_D3_Pin;
  GPIO_InitStruct.Mode = GPIO_MODE_AF_PP;
  GPIO_InitStruct.Pull = GPIO_NOPULL;
  GPIO_InitStruct.Speed = GPIO_SPEED_FREQ_LOW;
  GPIO_InitStruct.Alternate = GPIO_AF2_TIM5;
  HAL_GPIO_Init(ARD_D3_GPIO_Port, &GPIO_InitStruct);

  /*Configure GPIO pin : CTP_INT_Pin */
  GPIO_InitStruct.Pin = CTP_INT_Pin;
  GPIO_InitStruct.Mode = GPIO_MODE_IT_RISING;
  GPIO_InitStruct.Pull = GPIO_NOPULL;
  HAL_GPIO_Init(CTP_INT_GPIO_Port, &GPIO_InitStruct);

  /*Configure GPIO pin : B_USER_Pin */
  GPIO_InitStruct.Pin = B_USER_Pin;
  GPIO_InitStruct.Mode = GPIO_MODE_IT_RISING;
  GPIO_InitStruct.Pull = GPIO_NOPULL;
  HAL_GPIO_Init(B_USER_GPIO_Port, &GPIO_InitStruct);

  /*Configure GPIO pin : LED2_GREEN_Pin */
  GPIO_InitStruct.Pin = LED2_GREEN_Pin;
  GPIO_InitStruct.Mode = GPIO_MODE_OUTPUT_PP;
  GPIO_InitStruct.Pull = GPIO_NOPULL;
  GPIO_InitStruct.Speed = GPIO_SPEED_FREQ_LOW;
  HAL_GPIO_Init(LED2_GREEN_GPIO_Port, &GPIO_InitStruct);

  /*Configure GPIO pin : ARD_D6_Pin */
  GPIO_InitStruct.Pin = ARD_D6_Pin;
  GPIO_InitStruct.Mode = GPIO_MODE_AF_PP;
  GPIO_InitStruct.Pull = GPIO_NOPULL;
  GPIO_InitStruct.Speed = GPIO_SPEED_FREQ_LOW;
  GPIO_InitStruct.Alternate = GPIO_AF2_TIM3;
  HAL_GPIO_Init(ARD_D6_GPIO_Port, &GPIO_InitStruct);

  /*Configure GPIO pin : SD_Detect_Pin */
  GPIO_InitStruct.Pin = SD_Detect_Pin;
  GPIO_InitStruct.Mode = GPIO_MODE_IT_RISING;
  GPIO_InitStruct.Pull = GPIO_NOPULL;
  HAL_GPIO_Init(SD_Detect_GPIO_Port, &GPIO_InitStruct);

  /*Configure GPIO pins : ARD_D15_Pin ARD_D14_Pin */
  GPIO_InitStruct.Pin = ARD_D15_Pin|ARD_D14_Pin;
  GPIO_InitStruct.Mode = GPIO_MODE_AF_OD;
  GPIO_InitStruct.Pull = GPIO_PULLUP;
  GPIO_InitStruct.Speed = GPIO_SPEED_FREQ_VERY_HIGH;
  GPIO_InitStruct.Alternate = GPIO_AF4_I2C2;
  HAL_GPIO_Init(GPIOB, &GPIO_InitStruct);

  /*Configure GPIO pin : ARD_D13_Pin */
  GPIO_InitStruct.Pin = ARD_D13_Pin;
  GPIO_InitStruct.Mode = GPIO_MODE_AF_PP;
  GPIO_InitStruct.Pull = GPIO_NOPULL;
  GPIO_InitStruct.Speed = GPIO_SPEED_FREQ_VERY_HIGH;
  GPIO_InitStruct.Alternate = GPIO_AF7_SPI3;
  HAL_GPIO_Init(ARD_D13_GPIO_Port, &GPIO_InitStruct);

  /*Configure GPIO pins : LCD_CTP_RST_Pin LCD_TE_Pin WIFI_WKUP_Pin */
  GPIO_InitStruct.Pin = LCD_CTP_RST_Pin|LCD_TE_Pin|WIFI_WKUP_Pin;
  GPIO_InitStruct.Mode = GPIO_MODE_OUTPUT_PP;
  GPIO_InitStruct.Pull = GPIO_NOPULL;
  GPIO_InitStruct.Speed = GPIO_SPEED_FREQ_LOW;
  HAL_GPIO_Init(GPIOB, &GPIO_InitStruct);

  /*Configure GPIO pins : USB_OTG_FS_OVRCR_Pin CODEC_INT_Pin */
  GPIO_InitStruct.Pin = USB_OTG_FS_OVRCR_Pin|CODEC_INT_Pin;
  GPIO_InitStruct.Mode = GPIO_MODE_IT_RISING;
  GPIO_InitStruct.Pull = GPIO_NOPULL;
  HAL_GPIO_Init(GPIOG, &GPIO_InitStruct);

  /*Configure GPIO pins : USB_OTG_FS_PWR_EN_Pin ARD_D2_Pin */
  GPIO_InitStruct.Pin = USB_OTG_FS_PWR_EN_Pin|ARD_D2_Pin;
  GPIO_InitStruct.Mode = GPIO_MODE_OUTPUT_PP;
  GPIO_InitStruct.Pull = GPIO_NOPULL;
  GPIO_InitStruct.Speed = GPIO_SPEED_FREQ_LOW;
  HAL_GPIO_Init(GPIOG, &GPIO_InitStruct);

  /*Configure GPIO pin : ARD_D10_Pin */
  GPIO_InitStruct.Pin = ARD_D10_Pin;
  GPIO_InitStruct.Mode = GPIO_MODE_AF_PP;
  GPIO_InitStruct.Pull = GPIO_NOPULL;
  GPIO_InitStruct.Speed = GPIO_SPEED_FREQ_LOW;
  GPIO_InitStruct.Alternate = GPIO_AF1_TIM2;
  HAL_GPIO_Init(ARD_D10_GPIO_Port, &GPIO_InitStruct);

  /*Configure GPIO pins : ARD_D12_Pin ARD_D11_Pin */
  GPIO_InitStruct.Pin = ARD_D12_Pin|ARD_D11_Pin;
  GPIO_InitStruct.Mode = GPIO_MODE_AF_PP;
  GPIO_InitStruct.Pull = GPIO_NOPULL;
  GPIO_InitStruct.Speed = GPIO_SPEED_FREQ_VERY_HIGH;
  GPIO_InitStruct.Alternate = GPIO_AF6_SPI3;
  HAL_GPIO_Init(GPIOB, &GPIO_InitStruct);

  /*Configure GPIO pin : ARD_D4_Pin */
  GPIO_InitStruct.Pin = ARD_D4_Pin;
  GPIO_InitStruct.Mode = GPIO_MODE_IT_RISING;
  GPIO_InitStruct.Pull = GPIO_NOPULL;
  HAL_GPIO_Init(ARD_D4_GPIO_Port, &GPIO_InitStruct);

  /*Configure GPIO pin : ARD_D9_Pin */
  GPIO_InitStruct.Pin = ARD_D9_Pin;
  GPIO_InitStruct.Mode = GPIO_MODE_AF_PP;
  GPIO_InitStruct.Pull = GPIO_NOPULL;
  GPIO_InitStruct.Speed = GPIO_SPEED_FREQ_LOW;
  GPIO_InitStruct.Alternate = GPIO_AF2_TIM4;
  HAL_GPIO_Init(ARD_D9_GPIO_Port, &GPIO_InitStruct);

}

/* FSMC initialization function */
static void MX_FSMC_Init(void)
{

  FSMC_NORSRAM_TimingTypeDef Timing = {0};

  /** Perform the SRAM1 memory initialization sequence
  */
  hsram1.Instance = FSMC_NORSRAM_DEVICE;
  hsram1.Extended = FSMC_NORSRAM_EXTENDED_DEVICE;
  /* hsram1.Init */
  hsram1.Init.NSBank = FSMC_NORSRAM_BANK1;
  hsram1.Init.DataAddressMux = FSMC_DATA_ADDRESS_MUX_DISABLE;
  hsram1.Init.MemoryType = FSMC_MEMORY_TYPE_SRAM;
  hsram1.Init.MemoryDataWidth = FSMC_NORSRAM_MEM_BUS_WIDTH_16;
  hsram1.Init.BurstAccessMode = FSMC_BURST_ACCESS_MODE_DISABLE;
  hsram1.Init.WaitSignalPolarity = FSMC_WAIT_SIGNAL_POLARITY_LOW;
  hsram1.Init.WaitSignalActive = FSMC_WAIT_TIMING_BEFORE_WS;
  hsram1.Init.WriteOperation = FSMC_WRITE_OPERATION_DISABLE;
  hsram1.Init.WaitSignal = FSMC_WAIT_SIGNAL_DISABLE;
  hsram1.Init.ExtendedMode = FSMC_EXTENDED_MODE_DISABLE;
  hsram1.Init.AsynchronousWait = FSMC_ASYNCHRONOUS_WAIT_DISABLE;
  hsram1.Init.WriteBurst = FSMC_WRITE_BURST_DISABLE;
  hsram1.Init.ContinuousClock = FSMC_CONTINUOUS_CLOCK_SYNC_ONLY;
  hsram1.Init.WriteFifo = FSMC_WRITE_FIFO_ENABLE;
  hsram1.Init.PageSize = FSMC_PAGE_SIZE_NONE;
  /* Timing */
  Timing.AddressSetupTime = 15;
  Timing.AddressHoldTime = 15;
  Timing.DataSetupTime = 255;
  Timing.BusTurnAroundDuration = 15;
  Timing.CLKDivision = 16;
  Timing.DataLatency = 17;
  Timing.AccessMode = FSMC_ACCESS_MODE_A;
  /* ExtTiming */

  if (HAL_SRAM_Init(&hsram1, &Timing, NULL) != HAL_OK)
  {
    Error_Handler( );
  }

  /** Perform the SRAM2 memory initialization sequence
  */
  hsram2.Instance = FSMC_NORSRAM_DEVICE;
  hsram2.Extended = FSMC_NORSRAM_EXTENDED_DEVICE;
  /* hsram2.Init */
  hsram2.Init.NSBank = FSMC_NORSRAM_BANK3;
  hsram2.Init.DataAddressMux = FSMC_DATA_ADDRESS_MUX_DISABLE;
  hsram2.Init.MemoryType = FSMC_MEMORY_TYPE_SRAM;
  hsram2.Init.MemoryDataWidth = FSMC_NORSRAM_MEM_BUS_WIDTH_16;
  hsram2.Init.BurstAccessMode = FSMC_BURST_ACCESS_MODE_DISABLE;
  hsram2.Init.WaitSignalPolarity = FSMC_WAIT_SIGNAL_POLARITY_LOW;
  hsram2.Init.WaitSignalActive = FSMC_WAIT_TIMING_BEFORE_WS;
  hsram2.Init.WriteOperation = FSMC_WRITE_OPERATION_ENABLE;
  hsram2.Init.WaitSignal = FSMC_WAIT_SIGNAL_DISABLE;
  hsram2.Init.ExtendedMode = FSMC_EXTENDED_MODE_DISABLE;
  hsram2.Init.AsynchronousWait = FSMC_ASYNCHRONOUS_WAIT_DISABLE;
  hsram2.Init.WriteBurst = FSMC_WRITE_BURST_DISABLE;
  hsram2.Init.ContinuousClock = FSMC_CONTINUOUS_CLOCK_SYNC_ONLY;
  hsram2.Init.WriteFifo = FSMC_WRITE_FIFO_ENABLE;
  hsram2.Init.PageSize = FSMC_PAGE_SIZE_NONE;
  /* Timing */
  Timing.AddressSetupTime = 15;
  Timing.AddressHoldTime = 15;
  Timing.DataSetupTime = 255;
  Timing.BusTurnAroundDuration = 15;
  Timing.CLKDivision = 16;
  Timing.DataLatency = 17;
  Timing.AccessMode = FSMC_ACCESS_MODE_A;
  /* ExtTiming */

  if (HAL_SRAM_Init(&hsram2, &Timing, NULL) != HAL_OK)
  {
    Error_Handler( );
  }

}

void DefaultThread(void *argument)
{
  /* init code for USB_HOST */
  MX_USB_HOST_Init();
  /* USER CODE BEGIN 5 */
  /* Infinite loop */
  HAL_UART_Receive_IT(&huart6, Rx_Data, 4);
  for(;;)
  {
	HAL_GPIO_TogglePin(GPIOC, GPIO_PIN_5);
    osDelay(500);
  }
  /* USER CODE END 5 */
}

void MainThread(void *argument)
{
  /* USER CODE BEGIN MainThread */
  /* Infinite loop */
  for(;;)
  {
    osDelay(100);
  }
  /* USER CODE END MainThread */
}

void HAL_TIM_PeriodElapsedCallback(TIM_HandleTypeDef *htim)
{
  if (htim->Instance == TIM6) {
    HAL_IncTick();
  }
}

void Error_Handler(void)
{
}

/************************ (C) COPYRIGHT STMicroelectronics *****END OF FILE****/
